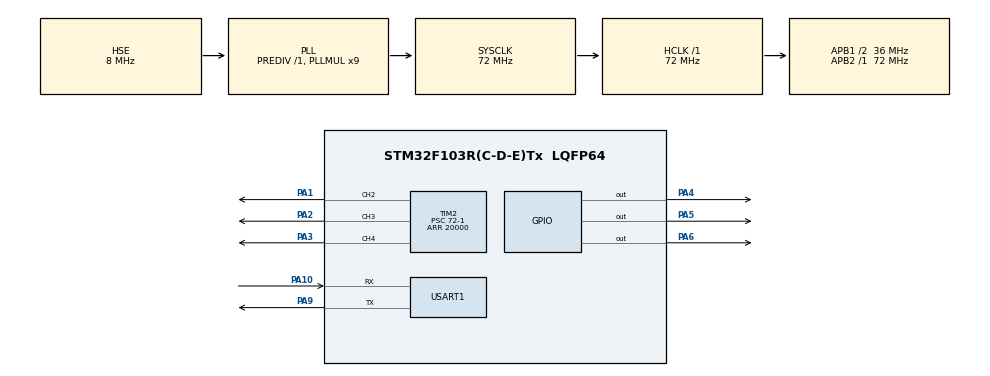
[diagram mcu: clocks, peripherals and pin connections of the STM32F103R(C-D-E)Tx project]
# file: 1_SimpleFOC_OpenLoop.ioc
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Mcu.Family=STM32F1
Mcu.Name=STM32F103R(C-D-E)Tx
Mcu.Package=LQFP64
NVIC.PriorityGroup=NVIC_PRIORITYGROUP_4
PA1.Signal=S_TIM2_CH2
PA10.Mode=Asynchronous
PA10.Signal=USART1_RX
PA13.Mode=Serial_Wire
PA13.Signal=SYS_JTMS-SWDIO
PA14.Mode=Serial_Wire
PA14.Signal=SYS_JTCK-SWCLK
PA2.Signal=S_TIM2_CH3
PA3.Signal=S_TIM2_CH4
PA4.Signal=GPIO_Output
PA5.GPIO_ModeDefaultOutputPP=GPIO_MODE_OUTPUT_OD
PA5.GPIO_PuPd=GPIO_NOPULL
PA5.GPIO_Speed=GPIO_SPEED_FREQ_HIGH
PA5.Signal=GPIO_Output
PA6.GPIO_ModeDefaultOutputPP=GPIO_MODE_OUTPUT_OD
PA6.GPIO_PuPd=GPIO_NOPULL
PA6.GPIO_Speed=GPIO_SPEED_FREQ_HIGH
PA6.Signal=GPIO_Output
PA9.Mode=Asynchronous
PA9.Signal=USART1_TX
PD0-OSC_IN.Mode=HSE-External-Oscillator
PD0-OSC_IN.Signal=RCC_OSC_IN
PD1-OSC_OUT.Mode=HSE-External-Oscillator
PD1-OSC_OUT.Signal=RCC_OSC_OUT
ProjectManager.HeapSize=0x200
ProjectManager.StackSize=0x400
ProjectManager.TargetToolchain=Makefile
RCC.AHBFreq_Value=72000000
RCC.APB1CLKDivider=RCC_HCLK_DIV2
RCC.APB1Freq_Value=36000000
RCC.APB1TimFreq_Value=72000000
RCC.APB2Freq_Value=72000000
RCC.APB2TimFreq_Value=72000000
RCC.HCLKFreq_Value=72000000
RCC.PLLMUL=RCC_PLL_MUL9
RCC.PLLSourceVirtual=RCC_PLLSOURCE_HSE
RCC.SYSCLKFreq_VALUE=72000000
RCC.SYSCLKSource=RCC_SYSCLKSOURCE_PLLCLK
RCC.USBFreq_Value=72000000
SH.S_TIM2_CH2.0=TIM2_CH2,PWM Generation2 CH2
SH.S_TIM2_CH3.0=TIM2_CH3,PWM Generation3 CH3
SH.S_TIM2_CH4.0=TIM2_CH4,PWM Generation4 CH4
TIM2.Channel-PWM\ Generation2\ CH2=TIM_CHANNEL_2
TIM2.Channel-PWM\ Generation3\ CH3=TIM_CHANNEL_3
TIM2.Channel-PWM\ Generation4\ CH4=TIM_CHANNEL_4
TIM2.Period=20000
TIM2.Prescaler=72-1
USART1.VirtualMode=VM_ASYNC
VP_TIM2_VS_ClockSourceINT.Mode=Internal
board=custom

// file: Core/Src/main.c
/* USER CODE BEGIN Header */
/**
 ******************************************************************************
 * @file           : main.c
 * @brief          : Main program body
 ******************************************************************************
 * @attention
 *
 * Copyright (c) 2024 STMicroelectronics.
 * All rights reserved.
 *
 * This software is licensed under terms that can be found in the LICENSE file
 * in the root directory of this software component.
 * If no LICENSE file comes with this software, it is provided AS-IS.
 *
 ******************************************************************************
 */
/* USER CODE END Header */
#include "main.h"
#include "tim.h"
#include "usart.h"
#include "gpio.h"

/* USER CODE BEGIN Includes */
#include "simpleFOC.h"
/* USER CODE END Includes */

void SystemClock_Config(void);

int main(void)
{

    /* MCU Configuration--------------------------------------------------------*/

    /* Reset of all peripherals, Initializes the Flash interface and the Systick. */
    HAL_Init();

    /* Configure the system clock */
    SystemClock_Config();

    /* Initialize all configured peripherals */
    MX_GPIO_Init();
    MX_TIM2_Init();
    MX_USART1_UART_Init();
    /* USER CODE BEGIN 2 */
    SimpleFOC_Init();
    /* USER CODE END 2 */

    /* Infinite loop */
    while (1) {

        /* USER CODE BEGIN 3 */
        SimpleFOC_RUN(Open_Loop, 10);
    }
    /* USER CODE END 3 */
}

void SystemClock_Config(void)
{
    RCC_OscInitTypeDef RCC_OscInitStruct = {0};
    RCC_ClkInitTypeDef RCC_ClkInitStruct = {0};

    /** Initializes the RCC Oscillators according to the specified parameters
     * in the RCC_OscInitTypeDef structure.
     */
    RCC_OscInitStruct.OscillatorType = RCC_OSCILLATORTYPE_HSE;
    RCC_OscInitStruct.HSEState       = RCC_HSE_ON;
    RCC_OscInitStruct.HSEPredivValue = RCC_HSE_PREDIV_DIV1;
    RCC_OscInitStruct.HSIState       = RCC_HSI_ON;
    RCC_OscInitStruct.PLL.PLLState   = RCC_PLL_ON;
    RCC_OscInitStruct.PLL.PLLSource  = RCC_PLLSOURCE_HSE;
    RCC_OscInitStruct.PLL.PLLMUL     = RCC_PLL_MUL9;
    if (HAL_RCC_OscConfig(&RCC_OscInitStruct) != HAL_OK) {
        Error_Handler();
    }

    /** Initializes the CPU, AHB and APB buses clocks
     */
    RCC_ClkInitStruct.ClockType      = RCC_CLOCKTYPE_HCLK | RCC_CLOCKTYPE_SYSCLK | RCC_CLOCKTYPE_PCLK1 | RCC_CLOCKTYPE_PCLK2;
    RCC_ClkInitStruct.SYSCLKSource   = RCC_SYSCLKSOURCE_PLLCLK;
    RCC_ClkInitStruct.AHBCLKDivider  = RCC_SYSCLK_DIV1;
    RCC_ClkInitStruct.APB1CLKDivider = RCC_HCLK_DIV2;
    RCC_ClkInitStruct.APB2CLKDivider = RCC_HCLK_DIV1;

    if (HAL_RCC_ClockConfig(&RCC_ClkInitStruct, FLASH_LATENCY_2) != HAL_OK) {
        Error_Handler();
    }
}

void Error_Handler(void)
{
    __disable_irq();
    while (1) {
    }
}
